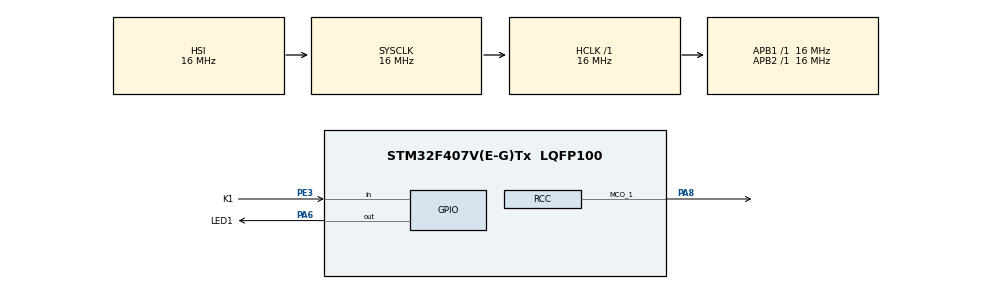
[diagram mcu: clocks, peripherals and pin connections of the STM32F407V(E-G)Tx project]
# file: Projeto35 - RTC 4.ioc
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Mcu.Family=STM32F4
Mcu.Name=STM32F407V(E-G)Tx
Mcu.Package=LQFP100
NVIC.PriorityGroup=NVIC_PRIORITYGROUP_4
NVIC.RTC_Alarm_IRQn=true\:0\:0\:false\:false\:true\:true\:true\:true
PA6.GPIO_Label=LED1
PA6.Signal=GPIO_Output
PA8.Mode=Clock-out-1
PA8.Signal=RCC_MCO_1
PC14-OSC32_IN.Mode=LSE-External-Oscillator
PC14-OSC32_IN.Signal=RCC_OSC32_IN
PC15-OSC32_OUT.Mode=LSE-External-Oscillator
PC15-OSC32_OUT.Signal=RCC_OSC32_OUT
PE3.GPIO_Label=K1
PE3.Signal=GPIO_Input
ProjectManager.HeapSize=0x200
ProjectManager.StackSize=0x400
ProjectManager.TargetToolchain=STM32CubeIDE
RCC.AHBFreq_Value=16000000
RCC.APB1Freq_Value=16000000
RCC.APB2Freq_Value=16000000
RCC.CortexFreq_Value=16000000
RCC.HSE_VALUE=25000000
RCC.HSI_VALUE=16000000
RCC.RCC_RTC_Clock_Source=RCC_RTCCLKSOURCE_LSE
RCC.RCC_RTC_Clock_SourceVirtual=RCC_RTCCLKSOURCE_LSE
RCC.SYSCLKFreq_VALUE=16000000
RCC.VCOOutputFreq_Value=192000000
RTC.Alarm=RTC_ALARM_A
RTC.Format=RTC_FORMAT_BIN
RTC.Hours=23
RTC.Minutes=59
RTC.Seconds=56
VP_RTC_VS_RTC_Activate.Mode=RTC_Enabled
VP_RTC_VS_RTC_Alarm_A_Intern.Mode=Alarm A
VP_RTC_VS_RTC_Calendar.Mode=RTC_Calendar
board=custom

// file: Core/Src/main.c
/* USER CODE BEGIN Header */
/**
  ******************************************************************************
  * @file           : main.c
  * @brief          : Main program body
  ******************************************************************************
  * @attention
  *
  * Copyright (c) 2023 STMicroelectronics.
  * All rights reserved.
  *
  * This software is licensed under terms that can be found in the LICENSE file
  * in the root directory of this software component.
  * If no LICENSE file comes with this software, it is provided AS-IS.
  *
  ******************************************************************************
  */
/* USER CODE END Header */
#include "main.h"

 RTC_HandleTypeDef hrtc;

/* USER CODE BEGIN PV */

 RTC_DateTypeDef data = {0};
 RTC_TimeTypeDef tempo = {0};
 RTC_AlarmTypeDef alarme = {0};

/* USER CODE END PV */

void SystemClock_Config(void);
static void MX_GPIO_Init(void);
static void MX_RTC_Init(void);

int main(void)
{

  /* MCU Configuration--------------------------------------------------------*/

  /* Reset of all peripherals, Initializes the Flash interface and the Systick. */
  HAL_Init();

  /* Configure the system clock */
  SystemClock_Config();

  /* Initialize all configured peripherals */
  MX_GPIO_Init();
  MX_RTC_Init();

  /* Infinite loop */
  while (1)
  {

    /* USER CODE BEGIN 3 */

	  HAL_RTC_GetDate(&hrtc, &data, RTC_FORMAT_BIN);
	  HAL_RTC_GetTime(&hrtc, &tempo, RTC_FORMAT_BIN);

	  if (HAL_GPIO_ReadPin(K1_GPIO_Port, K1_Pin) == GPIO_PIN_SET)
		  MX_RTC_Init();
  }
  /* USER CODE END 3 */
}

void SystemClock_Config(void)
{
  RCC_OscInitTypeDef RCC_OscInitStruct = {0};
  RCC_ClkInitTypeDef RCC_ClkInitStruct = {0};

  /** Configure the main internal regulator output voltage
  */
  __HAL_RCC_PWR_CLK_ENABLE();
  __HAL_PWR_VOLTAGESCALING_CONFIG(PWR_REGULATOR_VOLTAGE_SCALE1);

  /** Initializes the RCC Oscillators according to the specified parameters
  * in the RCC_OscInitTypeDef structure.
  */
  RCC_OscInitStruct.OscillatorType = RCC_OSCILLATORTYPE_HSI|RCC_OSCILLATORTYPE_LSE;
  RCC_OscInitStruct.LSEState = RCC_LSE_ON;
  RCC_OscInitStruct.HSIState = RCC_HSI_ON;
  RCC_OscInitStruct.HSICalibrationValue = RCC_HSICALIBRATION_DEFAULT;
  RCC_OscInitStruct.PLL.PLLState = RCC_PLL_NONE;
  if (HAL_RCC_OscConfig(&RCC_OscInitStruct) != HAL_OK)
  {
    Error_Handler();
  }

  /** Initializes the CPU, AHB and APB buses clocks
  */
  RCC_ClkInitStruct.ClockType = RCC_CLOCKTYPE_HCLK|RCC_CLOCKTYPE_SYSCLK
                              |RCC_CLOCKTYPE_PCLK1|RCC_CLOCKTYPE_PCLK2;
  RCC_ClkInitStruct.SYSCLKSource = RCC_SYSCLKSOURCE_HSI;
  RCC_ClkInitStruct.AHBCLKDivider = RCC_SYSCLK_DIV1;
  RCC_ClkInitStruct.APB1CLKDivider = RCC_HCLK_DIV1;
  RCC_ClkInitStruct.APB2CLKDivider = RCC_HCLK_DIV1;

  if (HAL_RCC_ClockConfig(&RCC_ClkInitStruct, FLASH_LATENCY_0) != HAL_OK)
  {
    Error_Handler();
  }
  HAL_RCC_MCOConfig(RCC_MCO1, RCC_MCO1SOURCE_HSI, RCC_MCODIV_1);
}

static void MX_RTC_Init(void)
{

  RTC_TimeTypeDef sTime = {0};
  RTC_DateTypeDef sDate = {0};
  RTC_AlarmTypeDef sAlarm = {0};

  /** Initialize RTC Only
  */
  hrtc.Instance = RTC;
  hrtc.Init.HourFormat = RTC_HOURFORMAT_24;
  hrtc.Init.AsynchPrediv = 127;
  hrtc.Init.SynchPrediv = 255;
  hrtc.Init.OutPut = RTC_OUTPUT_DISABLE;
  hrtc.Init.OutPutPolarity = RTC_OUTPUT_POLARITY_HIGH;
  hrtc.Init.OutPutType = RTC_OUTPUT_TYPE_OPENDRAIN;
  if (HAL_RTC_Init(&hrtc) != HAL_OK)
  {
    Error_Handler();
  }

  /** Initialize RTC and set the Time and Date
  */
  sTime.Hours = 23;
  sTime.Minutes = 59;
  sTime.Seconds = 56;
  sTime.DayLightSaving = RTC_DAYLIGHTSAVING_NONE;
  sTime.StoreOperation = RTC_STOREOPERATION_RESET;
  if (HAL_RTC_SetTime(&hrtc, &sTime, RTC_FORMAT_BIN) != HAL_OK)
  {
    Error_Handler();
  }
  sDate.WeekDay = RTC_WEEKDAY_MONDAY;
  sDate.Month = RTC_MONTH_JANUARY;
  sDate.Date = 1;
  sDate.Year = 0;

  if (HAL_RTC_SetDate(&hrtc, &sDate, RTC_FORMAT_BIN) != HAL_OK)
  {
    Error_Handler();
  }

  /** Enable the Alarm A
  */
  sAlarm.AlarmTime.Hours = 0;
  sAlarm.AlarmTime.Minutes = 0;
  sAlarm.AlarmTime.Seconds = 0;
  sAlarm.AlarmTime.SubSeconds = 0;
  sAlarm.AlarmTime.DayLightSaving = RTC_DAYLIGHTSAVING_NONE;
  sAlarm.AlarmTime.StoreOperation = RTC_STOREOPERATION_RESET;
  sAlarm.AlarmMask = RTC_ALARMMASK_NONE;
  sAlarm.AlarmSubSecondMask = RTC_ALARMSUBSECONDMASK_ALL;
  sAlarm.AlarmDateWeekDaySel = RTC_ALARMDATEWEEKDAYSEL_DATE;
  sAlarm.AlarmDateWeekDay = 1;
  sAlarm.Alarm = RTC_ALARM_A;
  if (HAL_RTC_SetAlarm_IT(&hrtc, &sAlarm, RTC_FORMAT_BIN) != HAL_OK)
  {
    Error_Handler();
  }

}

static void MX_GPIO_Init(void)
{
  GPIO_InitTypeDef GPIO_InitStruct = {0};

  /* GPIO Ports Clock Enable */
  __HAL_RCC_GPIOE_CLK_ENABLE();
  __HAL_RCC_GPIOC_CLK_ENABLE();
  __HAL_RCC_GPIOA_CLK_ENABLE();

  /*Configure GPIO pin Output Level */
  HAL_GPIO_WritePin(LED1_GPIO_Port, LED1_Pin, GPIO_PIN_RESET);

  /*Configure GPIO pin : K1_Pin */
  GPIO_InitStruct.Pin = K1_Pin;
  GPIO_InitStruct.Mode = GPIO_MODE_INPUT;
  GPIO_InitStruct.Pull = GPIO_NOPULL;
  HAL_GPIO_Init(K1_GPIO_Port, &GPIO_InitStruct);

  /*Configure GPIO pin : LED1_Pin */
  GPIO_InitStruct.Pin = LED1_Pin;
  GPIO_InitStruct.Mode = GPIO_MODE_OUTPUT_PP;
  GPIO_InitStruct.Pull = GPIO_NOPULL;
  GPIO_InitStruct.Speed = GPIO_SPEED_FREQ_LOW;
  HAL_GPIO_Init(LED1_GPIO_Port, &GPIO_InitStruct);

  /*Configure GPIO pin : PA8 */
  GPIO_InitStruct.Pin = GPIO_PIN_8;
  GPIO_InitStruct.Mode = GPIO_MODE_AF_PP;
  GPIO_InitStruct.Pull = GPIO_NOPULL;
  GPIO_InitStruct.Speed = GPIO_SPEED_FREQ_LOW;
  GPIO_InitStruct.Alternate = GPIO_AF0_MCO;
  HAL_GPIO_Init(GPIOA, &GPIO_InitStruct);

}

/* USER CODE BEGIN 4 */

void HAL_RTC_AlarmAEventCallback(RTC_HandleTypeDef *hrtc)
{
	HAL_GPIO_TogglePin(LED1_GPIO_Port, LED1_Pin);
}

/* USER CODE END 4 */

void Error_Handler(void)
{
  __disable_irq();
  while (1)
  {
  }
}
